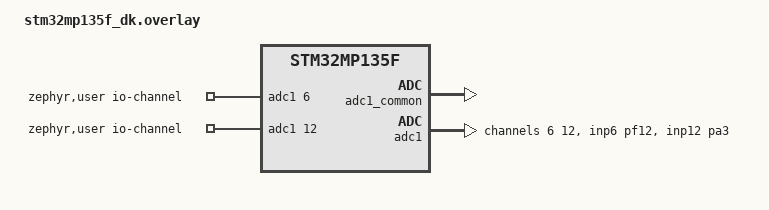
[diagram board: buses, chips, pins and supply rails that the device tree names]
/*
 * Copyright (c) 2026 STMicroelectronics
 *
 * SPDX-License-Identifier: Apache-2.0
 */

#include <zephyr/dt-bindings/adc/adc.h>

/ {
	zephyr,user {
		/* Type-C USB_PWR_CC1 and USB_PWR_CC2 */
		io-channels = <&adc1 6>, <&adc1 12>;
	};
};

&adc1_common {
	st,adc-prescaler = <4>;
	status = "okay";
};

&adc1 {
	pinctrl-0 = <&adc1_inp6_pf12 &adc1_inp12_pa3>;
	pinctrl-names = "default";
	#address-cells = <1>;
	#size-cells = <0>;
	status = "okay";

	/* Type-C USB_PWR_CC1 and USB_PWR_CC2 */
	channel@6 {
		reg = <6>;
		zephyr,gain = "ADC_GAIN_1";
		zephyr,reference = "ADC_REF_INTERNAL";
		zephyr,acquisition-time = <ADC_ACQ_TIME_DEFAULT>;
		zephyr,resolution = <12>;
	};

	channel@c {
		reg = <12>;
		zephyr,gain = "ADC_GAIN_1";
		zephyr,reference = "ADC_REF_INTERNAL";
		zephyr,acquisition-time = <ADC_ACQ_TIME_DEFAULT>;
		zephyr,resolution = <12>;
	};
};
